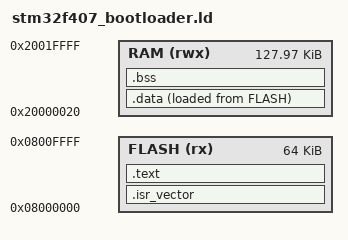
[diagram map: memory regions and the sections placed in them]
ENTRY(Reset_Handler)


MEMORY
{
    FLASH (rx)  : ORIGIN = 0x08000000, LENGTH = 64K
    RAM (rwx)   : ORIGIN = 0x20000020, LENGTH = 128K - 32
}

_estack = ORIGIN(RAM) + LENGTH(RAM);

SECTIONS
{
    .isr_vector :
    {
        . = ALIGN(4);
        KEEP(*(.isr_vector))
        . = ALIGN(4);
    } > FLASH

    .text :
    {
        . = ALIGN(4);
        *(.text)
        *(.text*)
        *(.rodata)
        *(.rodata*)
        *(.glue_7)
        *(.glue_7t)
        KEEP(*(.init))
        KEEP(*(.fini))
        . = ALIGN(4);
        _etext = .;
    } > FLASH

    .data :
    {
        . = ALIGN(4);
        _sdata = .;
        *(.data)
        *(.data*)
        . = ALIGN(4);
        _edata = .;
    } > RAM AT> FLASH

    _sidata = LOADADDR(.data);

    .bss :
    {
        . = ALIGN(4);
        _sbss = .;
        *(.bss)
        *(.bss*)
        *(COMMON)
        . = ALIGN(4);
        _ebss = .;
    } > RAM

    /DISCARD/ :
    {
        *(.ARM.exidx*)
        *(.ARM.attributes*)
    }
}
